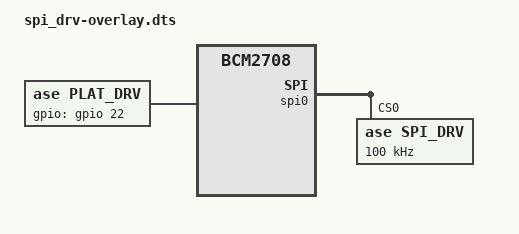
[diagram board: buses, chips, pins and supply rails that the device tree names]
/dts-v1/;
/plugin/;

/ {
    compatible = "brcm,bcm2835", "brcm,bcm2708";
    /* disable spi-dev for spi0.0 */
    fragment@0 {
        target = <&spi0>; // SPI Bus 0
        __overlay__ {
            status = "okay";
            spidev@0{     // SPI Chip Select 0
                status = "disabled";
            };
        };
    };

    fragment@1 {
        target = <&spi0>; // SPI Bus 0
        __overlay__ {
            /* needed to avoid dtc warning */
            #address-cells = <1>;
            #size-cells = <0>;
            spi_drv:spi_drv@0 {
                compatible = "ase, spi_drv";
                reg = <0>; // SPI Chip Select 0
                spi-cpha; /* Comment in to set CPHA */
                spi-cpol; /* Comment in to set CPOL */
                spi-max-frequency = <100000>;
            };
        };
    };
    fragment@2 {
        /* Add device to base */
        target-path = "/";
        __overlay__ {
            /* instance:type */
            plat_drv: plat_drv@0 {
                /* Label to match in driver */
                compatible = "ase, plat_drv";

                /* Configure gpio module */
                /* <ressource pinno dir pinno dir pinno dir ....> */
                gpios = <&gpio 22 0>; 

                status = "okay";
            };
        };
    };
};
